AUTOSAR XML (schema 00049)
package /ServerApp
  process design ServerDesign: executable=serverd
package /ServerApp/exe
  executable serverd: category=APPLICATION_LEVEL, logging-behavior=USES-LOGGING, reporting-behavior=REPORTS-EXECUTION-STATE
    root sw component prototype server: application-type=server
package /ServerApp/swc
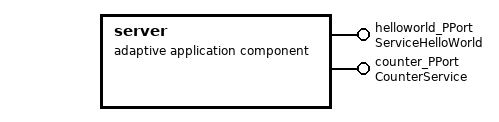
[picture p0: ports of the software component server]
  adaptive application sw component type server
    provide port helloworld_PPort: provided-interface=ServiceHelloWorld
    provide port counter_PPort: provided-interface=CounterService
